AUTOSAR XML (schema 00048)
package /ComponentTypes
  swc implementation IPC_Implementation: behavior=IPC_InternalBehavior
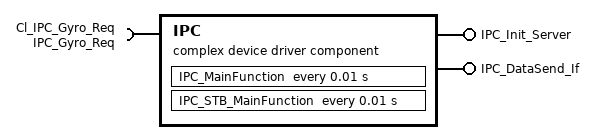
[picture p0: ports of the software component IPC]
  complex device driver sw component type IPC
    require port Cl_IPC_Gyro_Req: client-com-spec=Operation, required-interface=IPC_Gyro_Req
    provide port IPC_Init_Server: server-com-spec{operation=Operation, queue-length=1}, provided-interface=IPC_Init_Server
    provide port IPC_DataSend_If: server-com-spec{operation=Operation, queue-length=1}, provided-interface=IPC_DataSend_If
    behavior IPC_InternalBehavior: port-api-option{enable-take-address=true, error-handling=NO-TRANSFORMER-ERROR-HANDLING, indirect-api=false, port=IPC_Init_Server}
      exclusive area ExclusiveArea_IPC
      exclusive area ExclusiveArea_IPC_STB
      timing event TMT_IPC_MainFunction: start-on-event=IPC_MainFunction, period=0.01
      operation invoked event OIT_IPC_Init_Server_Operation_IPC_Init_Server_Operation: start-on-event=IPC_Init, operation=IPC_Init_Server.Operation
      operation invoked event OIT_IPC_DataSend_If_Operation_IPC_DataSend_If_Operation: start-on-event=IPC_DataSend_If_Operation, operation=IPC_DataSend_If.Operation
      timing event TMT_IPC_STB_MainFunction: start-on-event=IPC_STB_MainFunction, period=0.01
      4 x runnable:
        IPC_MainFunction: can-enter-exclusive-area=ExclusiveArea_IPC
          sync call SC_Cl_IPC_Gyro_Req_Operation: operation=Cl_IPC_Gyro_Req.Operation
        IPC_Init
        IPC_DataSend_If_Operation
        IPC_STB_MainFunction: can-enter-exclusive-area=ExclusiveArea_IPC_STB
